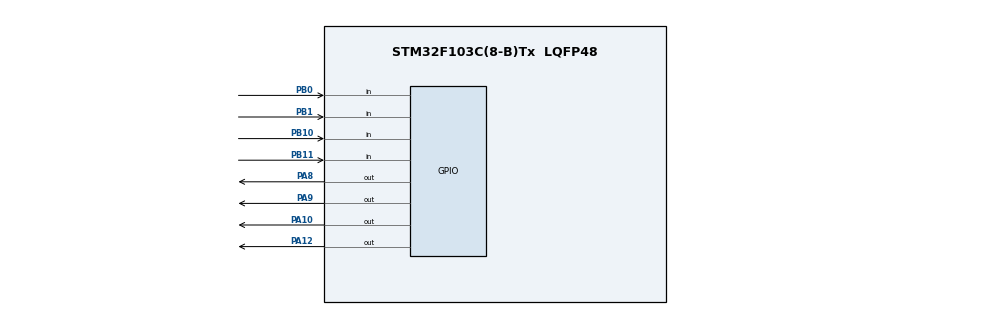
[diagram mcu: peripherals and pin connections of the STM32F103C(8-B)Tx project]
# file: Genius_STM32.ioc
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Mcu.Family=STM32F1
Mcu.Name=STM32F103C(8-B)Tx
Mcu.Package=LQFP48
NVIC.PriorityGroup=NVIC_PRIORITYGROUP_4
PA10.Signal=GPIO_Output
PA12.Signal=GPIO_Output
PA13.Signal=SYS_JTMS-SWDIO
PA14.Signal=SYS_JTCK-SWCLK
PA8.Signal=GPIO_Output
PA9.Signal=GPIO_Output
PB0.Signal=GPIO_Input
PB1.Signal=GPIO_Input
PB10.Signal=GPIO_Input
PB11.Signal=GPIO_Input
ProjectManager.HeapSize=0x200
ProjectManager.StackSize=0x400
ProjectManager.TargetToolchain=STM32CubeIDE
RCC.APB1Freq_Value=8000000
RCC.APB2Freq_Value=8000000
VP_SYS_VS_ND.Mode=No_Debug
board=custom

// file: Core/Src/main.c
/* USER CODE BEGIN Header */
/**
  ******************************************************************************
  * @file           : main.c
  * @brief          : Main program body
  ******************************************************************************
  * @attention
  *
  * Copyright (c) 2022 STMicroelectronics.
  * All rights reserved.
  *
  * This software is licensed under terms that can be found in the LICENSE file
  * in the root directory of this software component.
  * If no LICENSE file comes with this software, it is provided AS-IS.
  *
  ******************************************************************************
  */
/* USER CODE END Header */
#include "main.h"

/* USER CODE BEGIN PV */
int sequencia[32] = {};
int botoes[4] = {7, 6, 5, 4};
int leds[4] = {8, 9, 10, 11};
int tons[4] = {262, 294, 330, 349};
int rodada = 0;
int passo = 0;

int true = 1;
int false = 0;
int game_over = 0; // começa com false
/* USER CODE END PV */

void SystemClock_Config(void);
static void MX_GPIO_Init(void);
/* USER CODE BEGIN PFP */
void proximaRodada();
void reproduzirSequencia();
void aguardarJogador();

/* USER CODE END PFP */

int main(void)
{

  /* MCU Configuration--------------------------------------------------------*/

  /* Reset of all peripherals, Initializes the Flash interface and the Systick. */
  HAL_Init();

  /* Configure the system clock */
  SystemClock_Config();

  /* Initialize all configured peripherals */
  MX_GPIO_Init();

  /* Infinite loop */
  /* USER CODE BEGIN WHILE */
  while (1)
  {
	      //LED VERMELHO: HAL_GPIO_WritePin(GPIOA,GPIO_PIN_12, 1); LED 0
	  	  //LED AZUL: HAL_GPIO_WritePin(GPIOA,GPIO_PIN_10, 1);     LED 1
	  	  //LED VERDE: HAL_GPIO_WritePin(GPIOA,GPIO_PIN_9, 1);     LED 2
	  	  //LED AMARELO: HAL_GPIO_WritePin(GPIOA,GPIO_PIN_8, 1);   LED 3

	  	  //BOTAO VERMELHO: HAL_GPIO_ReadPin(GPIOB, GPIO_PIN_0) == 1  BOTAO 0
	  	  //BOTAO AZUL: HAL_GPIO_ReadPin(GPIOB, GPIO_PIN_1) == 1     BOTAO 1
	  	  //BOTAO VERDE: HAL_GPIO_ReadPin(GPIOB, GPIO_PIN_10) == 1   BOTAO 2
	  	  //BOTAO AMARELO: HAL_GPIO_ReadPin(GPIOB, GPIO_PIN_11) == 1  BOTAO 3

	  	  	proximaRodada();
	 	    reproduzirSequencia();
	 	    aguardarJogador();
	 	    // estrutura usada para reiniciar todas as variáveis (novo jogo)
	 	    if (game_over == true) {
	 	    	for(int i=0;i<32;i++)
	 	    			sequencia[i] = 0; // caso comentar, não dá erros
	 	      rodada = 0;
	 	      passo = 0;
	 	      game_over = false;
	 	    }
	 	    HAL_Delay(1000);

    /* USER CODE END WHILE */

  }
}

void SystemClock_Config(void)
{
  RCC_OscInitTypeDef RCC_OscInitStruct = {0};
  RCC_ClkInitTypeDef RCC_ClkInitStruct = {0};

  /** Initializes the RCC Oscillators according to the specified parameters
  * in the RCC_OscInitTypeDef structure.
  */
  RCC_OscInitStruct.OscillatorType = RCC_OSCILLATORTYPE_HSI;
  RCC_OscInitStruct.HSIState = RCC_HSI_ON;
  RCC_OscInitStruct.HSICalibrationValue = RCC_HSICALIBRATION_DEFAULT;
  RCC_OscInitStruct.PLL.PLLState = RCC_PLL_NONE;
  if (HAL_RCC_OscConfig(&RCC_OscInitStruct) != HAL_OK)
  {
    Error_Handler();
  }
  /** Initializes the CPU, AHB and APB buses clocks
  */
  RCC_ClkInitStruct.ClockType = RCC_CLOCKTYPE_HCLK|RCC_CLOCKTYPE_SYSCLK
                              |RCC_CLOCKTYPE_PCLK1|RCC_CLOCKTYPE_PCLK2;
  RCC_ClkInitStruct.SYSCLKSource = RCC_SYSCLKSOURCE_HSI;
  RCC_ClkInitStruct.AHBCLKDivider = RCC_SYSCLK_DIV1;
  RCC_ClkInitStruct.APB1CLKDivider = RCC_HCLK_DIV1;
  RCC_ClkInitStruct.APB2CLKDivider = RCC_HCLK_DIV1;

  if (HAL_RCC_ClockConfig(&RCC_ClkInitStruct, FLASH_LATENCY_0) != HAL_OK)
  {
    Error_Handler();
  }
}

static void MX_GPIO_Init(void)
{
  GPIO_InitTypeDef GPIO_InitStruct = {0};

  /* GPIO Ports Clock Enable */
  __HAL_RCC_GPIOB_CLK_ENABLE();
  __HAL_RCC_GPIOA_CLK_ENABLE();

  /*Configure GPIO pin Output Level */
  HAL_GPIO_WritePin(GPIOA, GPIO_PIN_8|GPIO_PIN_9|GPIO_PIN_10|GPIO_PIN_11
                          |GPIO_PIN_12, GPIO_PIN_RESET);

  /*Configure GPIO pins : PB0 PB1 PB10 PB11 */
  GPIO_InitStruct.Pin = GPIO_PIN_0|GPIO_PIN_1|GPIO_PIN_10|GPIO_PIN_11;
  GPIO_InitStruct.Mode = GPIO_MODE_INPUT;
  GPIO_InitStruct.Pull = GPIO_NOPULL;
  HAL_GPIO_Init(GPIOB, &GPIO_InitStruct);

  /*Configure GPIO pins : PA8 PA9 PA10 PA11
                           PA12 */
  GPIO_InitStruct.Pin = GPIO_PIN_8|GPIO_PIN_9|GPIO_PIN_10|GPIO_PIN_11
                          |GPIO_PIN_12;
  GPIO_InitStruct.Mode = GPIO_MODE_OUTPUT_PP;
  GPIO_InitStruct.Pull = GPIO_NOPULL;
  GPIO_InitStruct.Speed = GPIO_SPEED_FREQ_LOW;
  HAL_GPIO_Init(GPIOA, &GPIO_InitStruct);

}

/* USER CODE BEGIN 4 */
//insrindo funções inicio
void proximaRodada() {

  int sorteio = rand()%4; //comando correto:  int sorteio = random(4);

  sequencia[rodada] = sorteio;
  rodada = rodada + 1;
  //Serial.print(sorteio);
}

void reproduzirSequencia() {
  for (int i = 0; i < rodada; i++) {

        if(leds[sequencia[i]] == leds[0]){// 8 é o pino
            HAL_GPIO_WritePin(GPIOA,GPIO_PIN_12, 1);
            HAL_Delay(500);
            HAL_GPIO_WritePin(GPIOA,GPIO_PIN_12, 0);
            HAL_Delay(100);
          }

      else  if(leds[sequencia[i]] == leds[1]){
          HAL_GPIO_WritePin(GPIOA,GPIO_PIN_10, 1);
          HAL_Delay(500);
          HAL_GPIO_WritePin(GPIOA,GPIO_PIN_10, 0);
          HAL_Delay(100);
        }

      else  if(leds[sequencia[i]] == leds[2]){
      HAL_GPIO_WritePin(GPIOA,GPIO_PIN_9, 1);
      HAL_Delay(500);
      HAL_GPIO_WritePin(GPIOA,GPIO_PIN_9, 0);
      HAL_Delay(100);
    }

      else  if(leds[sequencia[i]] == leds[3]){
          HAL_GPIO_WritePin(GPIOA,GPIO_PIN_8, 1);
          HAL_Delay(500);
          HAL_GPIO_WritePin(GPIOA,GPIO_PIN_8, 0);
          HAL_Delay(100);
        }

  }
}

void aguardarJogador() {
  int botao_pressionado = 0;
  for (int i = 0; i < rodada; i++) {
     int jogada_efetuada = false;
    while (jogada_efetuada == false) {
      for (int i = 0; i <= 3; i++) {
         if (HAL_GPIO_ReadPin(GPIOB, GPIO_PIN_0) == 1) {
          botao_pressionado = 0;

          HAL_GPIO_WritePin(GPIOA,GPIO_PIN_12, 1);
          HAL_Delay(300);
          HAL_GPIO_WritePin(GPIOA,GPIO_PIN_12, 0);

          jogada_efetuada = true;
        }

        else if (HAL_GPIO_ReadPin(GPIOB, GPIO_PIN_1) == 1) {
          botao_pressionado = 1;

          HAL_GPIO_WritePin(GPIOA,GPIO_PIN_10, 1);
          HAL_Delay(300);
          HAL_GPIO_WritePin(GPIOA,GPIO_PIN_10, 0);

          jogada_efetuada = true;
        }

        else if (HAL_GPIO_ReadPin(GPIOB, GPIO_PIN_10) == 1) {
          botao_pressionado = 2;

          HAL_GPIO_WritePin(GPIOA,GPIO_PIN_9, 1);
          HAL_Delay(300);
          HAL_GPIO_WritePin(GPIOA,GPIO_PIN_9, 0);

          jogada_efetuada = true;
        }

        else if (HAL_GPIO_ReadPin(GPIOB, GPIO_PIN_11) == 1) {
          botao_pressionado = 3;

          HAL_GPIO_WritePin(GPIOA,GPIO_PIN_8, 1);
          HAL_Delay(300);
          HAL_GPIO_WritePin(GPIOA,GPIO_PIN_8, 0);

          jogada_efetuada = true;
        }

      }
    }
    //verificar a jogada
    if (sequencia[passo] != botao_pressionado) {
      //efeito luminoso/sonoro indicando que o jogador perdeu
      for (int i = 0; i <= 3; i++) {

            if(i == 0){
              HAL_GPIO_WritePin(GPIOA,GPIO_PIN_12, 1);
              HAL_Delay(100);
              HAL_GPIO_WritePin(GPIOA,GPIO_PIN_12, 0);
              }

            else if(i == 1){
              HAL_GPIO_WritePin(GPIOA,GPIO_PIN_10, 1);
              HAL_Delay(100);
              HAL_GPIO_WritePin(GPIOA,GPIO_PIN_10, 0);
              }

            else if(i == 2){
              HAL_GPIO_WritePin(GPIOA,GPIO_PIN_9, 1);
              HAL_Delay(100);
              HAL_GPIO_WritePin(GPIOA,GPIO_PIN_9, 0);
              }

            else if(i == 3){
              HAL_GPIO_WritePin(GPIOA,GPIO_PIN_8, 1);
              HAL_Delay(100);
              HAL_GPIO_WritePin(GPIOA,GPIO_PIN_8, 0);
          }

      }
      game_over = true;
      break;
    }
    passo = passo + 1;
  }
  passo = 0;
}

//inserindo funções fim

/* USER CODE END 4 */

void Error_Handler(void)
{
  __disable_irq();
  while (1)
  {
  }
}

/************************ (C) COPYRIGHT STMicroelectronics *****END OF FILE****/
